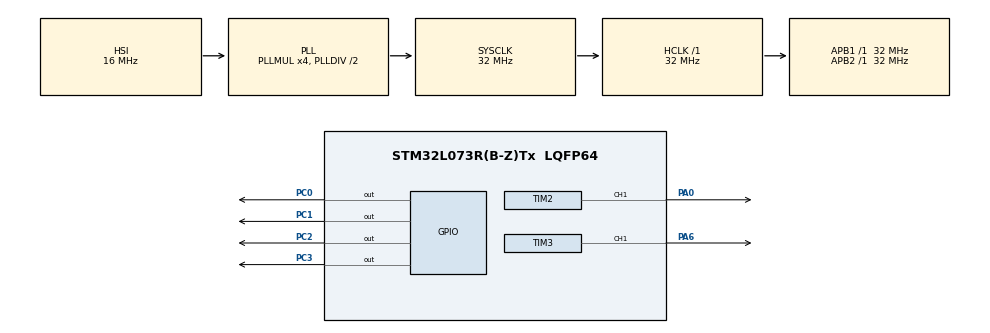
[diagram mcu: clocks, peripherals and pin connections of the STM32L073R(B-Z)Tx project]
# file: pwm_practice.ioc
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Mcu.Family=STM32L0
Mcu.Name=STM32L073R(B-Z)Tx
Mcu.Package=LQFP64
PA0.Signal=S_TIM2_CH1
PA6.Signal=S_TIM3_CH1
PC0.GPIO_PuPd=GPIO_PULLDOWN
PC0.Signal=GPIO_Output
PC1.GPIO_PuPd=GPIO_PULLDOWN
PC1.Signal=GPIO_Output
PC2.Signal=GPIO_Output
PC3.Signal=GPIO_Output
ProjectManager.HeapSize=0x200
ProjectManager.StackSize=0x400
ProjectManager.TargetToolchain=MDK-ARM V5
RCC.AHBFreq_Value=32000000
RCC.APB1Freq_Value=32000000
RCC.APB1TimFreq_Value=32000000
RCC.APB2Freq_Value=32000000
RCC.APB2TimFreq_Value=32000000
RCC.HCLKFreq_Value=32000000
RCC.HSE_VALUE=8000000
RCC.HSI16_VALUE=16000000
RCC.HSI48_VALUE=48000000
RCC.HSI_VALUE=16000000
RCC.LSE_VALUE=32768
RCC.MSI_VALUE=2097000
RCC.PLLMUL=RCC_PLLMUL_4
RCC.SYSCLKFreq_VALUE=32000000
RCC.SYSCLKSource=RCC_SYSCLKSOURCE_PLLCLK
RCC.VCOOutputFreq_Value=64000000
SH.S_TIM2_CH1.0=TIM2_CH1,PWM Generation1 CH1
SH.S_TIM3_CH1.0=TIM3_CH1,PWM Generation1 CH1
TIM2.Channel-PWM\ Generation1\ CH1=TIM_CHANNEL_1
TIM2.Period=999
TIM2.Prescaler=32
TIM2.Pulse-PWM\ Generation1\ CH1=499
TIM3.Channel-PWM\ Generation1\ CH1=TIM_CHANNEL_1
TIM3.Period=999
TIM3.Prescaler=32
TIM3.Pulse-PWM\ Generation1\ CH1=499
TIM6.Period=999
TIM6.Prescaler=3200
VP_TIM6_VS_ClockSourceINT.Mode=Enable_Timer
board=custom

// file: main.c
/**
  ******************************************************************************
  * @file           : main.c
  * @brief          : Main program body
  ******************************************************************************
  ** This notice applies to any and all portions of this file
  * that are not between comment pairs USER CODE BEGIN and
  * USER CODE END. Other portions of this file, whether
  * inserted by the user or by software development tools
  * are owned by their respective copyright owners.
  *
  * COPYRIGHT(c) 2018 STMicroelectronics
  *
  * Redistribution and use in source and binary forms, with or without modification,
  * are permitted provided that the following conditions are met:
  *   1. Redistributions of source code must retain the above copyright notice,
  *      this list of conditions and the following disclaimer.
  *   2. Redistributions in binary form must reproduce the above copyright notice,
  *      this list of conditions and the following disclaimer in the documentation
  *      and/or other materials provided with the distribution.
  *   3. Neither the name of STMicroelectronics nor the names of its contributors
  *      may be used to endorse or promote products derived from this software
  *      without specific prior written permission.
  *
  * THIS SOFTWARE IS PROVIDED BY THE COPYRIGHT HOLDERS AND CONTRIBUTORS "AS IS"
  * AND ANY EXPRESS OR IMPLIED WARRANTIES, INCLUDING, BUT NOT LIMITED TO, THE
  * IMPLIED WARRANTIES OF MERCHANTABILITY AND FITNESS FOR A PARTICULAR PURPOSE ARE
  * DISCLAIMED. IN NO EVENT SHALL THE COPYRIGHT HOLDER OR CONTRIBUTORS BE LIABLE
  * FOR ANY DIRECT, INDIRECT, INCIDENTAL, SPECIAL, EXEMPLARY, OR CONSEQUENTIAL
  * DAMAGES (INCLUDING, BUT NOT LIMITED TO, PROCUREMENT OF SUBSTITUTE GOODS OR
  * SERVICES; LOSS OF USE, DATA, OR PROFITS; OR BUSINESS INTERRUPTION) HOWEVER
  * CAUSED AND ON ANY THEORY OF LIABILITY, WHETHER IN CONTRACT, STRICT LIABILITY,
  * OR TORT (INCLUDING NEGLIGENCE OR OTHERWISE) ARISING IN ANY WAY OUT OF THE USE
  * OF THIS SOFTWARE, EVEN IF ADVISED OF THE POSSIBILITY OF SUCH DAMAGE.
  *
  ******************************************************************************
  */
#include "main.h"
#include "stm32l0xx_hal.h"
#include "tim.h"
#include "gpio.h"

/* USER CODE BEGIN PV */

int i=0;
int g=1;
int temp;

uint8_t str[6] = {0};
uint8_t val = 0;

/* Private variables ---------------------------------------------------------*/

/* USER CODE END PV */

void SystemClock_Config(void);

/* USER CODE BEGIN PFP */
/* Private function prototypes -----------------------------------------------*/
void HAL_TIM_PeriodElapsedCallback(TIM_HandleTypeDef *htim){
		/*if(htim->Instance == TIM2)
		{
			if(TIM2->CCR1 == 500) TIM2->CCR1 = 0;
			else TIM2->CCR1 += 1;
		}else if(htim->Instance == TIM3)
		{
			if(TIM3->CCR1 == 999) TIM3->CCR1 = 0;
			else TIM3->CCR1 += 1;
		}*/
	}
/* USER CODE END PFP */

int main(void)
{

  /* MCU Configuration----------------------------------------------------------*/

  /* Reset of all peripherals, Initializes the Flash interface and the Systick. */
  HAL_Init();

  /* Configure the system clock */
  SystemClock_Config();

  /* Initialize all configured peripherals */
  MX_GPIO_Init();
  MX_TIM2_Init();
  MX_TIM3_Init();
  MX_TIM6_Init();
  /* USER CODE BEGIN 2 */
	HAL_TIM_PWM_Start(&htim2,TIM_CHANNEL_1);
	HAL_TIM_PWM_Start(&htim3,TIM_CHANNEL_1);
  /* USER CODE END 2 */

  /* Infinite loop */
  /* USER CODE BEGIN WHILE */
			HAL_GPIO_WritePin(GPIOC, GPIO_PIN_0, GPIO_PIN_SET);
			HAL_GPIO_WritePin(GPIOC, GPIO_PIN_1, GPIO_PIN_RESET);
			HAL_GPIO_WritePin(GPIOC, GPIO_PIN_2, GPIO_PIN_SET);
			HAL_GPIO_WritePin(GPIOC, GPIO_PIN_3, GPIO_PIN_RESET);

	while (1)
  {

  /* USER CODE END WHILE */

	}

}

void SystemClock_Config(void)
{

  RCC_OscInitTypeDef RCC_OscInitStruct;
  RCC_ClkInitTypeDef RCC_ClkInitStruct;

    /**Configure the main internal regulator output voltage
    */
  __HAL_PWR_VOLTAGESCALING_CONFIG(PWR_REGULATOR_VOLTAGE_SCALE1);

    /**Initializes the CPU, AHB and APB busses clocks
    */
  RCC_OscInitStruct.OscillatorType = RCC_OSCILLATORTYPE_HSI;
  RCC_OscInitStruct.HSIState = RCC_HSI_ON;
  RCC_OscInitStruct.HSICalibrationValue = 16;
  RCC_OscInitStruct.PLL.PLLState = RCC_PLL_ON;
  RCC_OscInitStruct.PLL.PLLSource = RCC_PLLSOURCE_HSI;
  RCC_OscInitStruct.PLL.PLLMUL = RCC_PLLMUL_4;
  RCC_OscInitStruct.PLL.PLLDIV = RCC_PLLDIV_2;
  if (HAL_RCC_OscConfig(&RCC_OscInitStruct) != HAL_OK)
  {
    _Error_Handler(__FILE__, __LINE__);
  }

    /**Initializes the CPU, AHB and APB busses clocks
    */
  RCC_ClkInitStruct.ClockType = RCC_CLOCKTYPE_HCLK|RCC_CLOCKTYPE_SYSCLK
                              |RCC_CLOCKTYPE_PCLK1|RCC_CLOCKTYPE_PCLK2;
  RCC_ClkInitStruct.SYSCLKSource = RCC_SYSCLKSOURCE_PLLCLK;
  RCC_ClkInitStruct.AHBCLKDivider = RCC_SYSCLK_DIV1;
  RCC_ClkInitStruct.APB1CLKDivider = RCC_HCLK_DIV1;
  RCC_ClkInitStruct.APB2CLKDivider = RCC_HCLK_DIV1;

  if (HAL_RCC_ClockConfig(&RCC_ClkInitStruct, FLASH_LATENCY_1) != HAL_OK)
  {
    _Error_Handler(__FILE__, __LINE__);
  }

    /**Configure the Systick interrupt time
    */
  HAL_SYSTICK_Config(HAL_RCC_GetHCLKFreq()/1000);

    /**Configure the Systick
    */
  HAL_SYSTICK_CLKSourceConfig(SYSTICK_CLKSOURCE_HCLK);

  /* SysTick_IRQn interrupt configuration */
  HAL_NVIC_SetPriority(SysTick_IRQn, 0, 0);
}

void _Error_Handler(char *file, int line)
{
  while(1)
  {
  }
}

/************************ (C) COPYRIGHT STMicroelectronics *****END OF FILE****/
